VERSION "HIPBNYYYYYYYYYYYYYYYYYYYYYYYYYYYYYYYYYYYYY/4/%%%/4/'%**4YYY///"

NS_ :

BS_:

BU_: PCM1

BO_ 3221225472 VECTOR__INDEPENDENT_SIG_MSG: 0 Vector__XXX
 SG_ Enable : 0|1@0+ (1,0) [0|1] "" Vector__XXX
 SG_ EngineSpeed : 0|16@0+ (0.1,0) [0|6500] "rpm" Vector__XXX
 SG_ EngineTemperature : 0|16@0+ (0.01,-40) [-40|500] "degC" Vector__XXX

BO_ 777 Counter: 8 Vector__XXX
 SG_ CounterValue : 7|32@0+ (1,0) [0|0] "" Vector__XXX

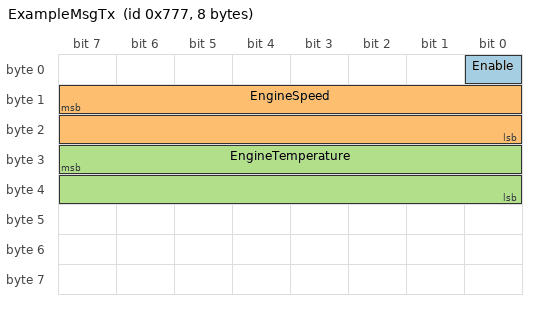
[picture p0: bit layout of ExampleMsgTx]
BO_ 1911 ExampleMsgTx: 8 PCM1
 SG_ Enable : 0|1@0+ (1,0) [0|1] "" Vector__XXX
 SG_ EngineSpeed : 15|16@0+ (0.1,0) [0|6500] "rpm" Vector__XXX
 SG_ EngineTemperature : 31|16@0+ (0.01,-40) [-40|500] "degC" Vector__XXX

BO_ 2147488308 ExampleMsgRx: 8 PCM1
 SG_ CountUpByValue : 7|16@0+ (1,0) [0|0] "" Vector__XXX

CM_ BO_ 3221225472 "This is a message for not used signals, created by Vector CANdb++ DBC OLE DB Provider.";
CM_ BO_ 1911 "Example message";
CM_ BO_ 2147488308 "Example message";
